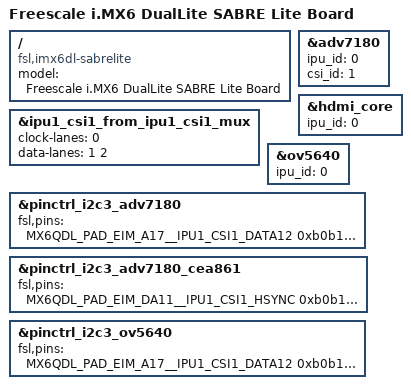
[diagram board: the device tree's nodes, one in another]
// SPDX-License-Identifier: GPL-2.0 OR X11
/*
 * Copyright 2013 Boundary Devices, Inc.
 * Copyright 2012 Freescale Semiconductor, Inc.
 * Copyright 2011 Linaro Ltd.
 */

/dts-v1/;
#include "imx6dl.dtsi"
#include "imx6qdl-sabrelite.dtsi"

/ {
	model = "Freescale i.MX6 DualLite SABRE Lite Board";
	compatible = "fsl,imx6dl-sabrelite", "fsl,imx6dl";
};

&adv7180 {
	ipu_id = <0>;
	csi_id = <1>;
};

&hdmi_core {
	ipu_id = <0>;
};

&ipu1_csi1_from_ipu1_csi1_mux {
	clock-lanes = <0>;
	data-lanes = <1 2>;
};

&ov5640 {
	ipu_id = <0>;
};

&pinctrl_i2c3_adv7180 {
	fsl,pins = <
		MX6QDL_PAD_EIM_A17__IPU1_CSI1_DATA12	0xb0b1
		MX6QDL_PAD_EIM_A18__IPU1_CSI1_DATA13	0xb0b1
		MX6QDL_PAD_EIM_A19__IPU1_CSI1_DATA14	0xb0b1
		MX6QDL_PAD_EIM_A20__IPU1_CSI1_DATA15	0xb0b1
		MX6QDL_PAD_EIM_A21__IPU1_CSI1_DATA16	0xb0b1
		MX6QDL_PAD_EIM_A22__IPU1_CSI1_DATA17	0xb0b1
		MX6QDL_PAD_EIM_A23__IPU1_CSI1_DATA18	0xb0b1
		MX6QDL_PAD_EIM_EB2__IPU1_CSI1_DATA19	0xb0b1
		MX6QDL_PAD_EIM_A16__IPU1_CSI1_PIXCLK	0xb0b1
       >;
};

&pinctrl_i2c3_adv7180_cea861 {
	fsl,pins = <
		MX6QDL_PAD_EIM_DA11__IPU1_CSI1_HSYNC	0xb0b1
		MX6QDL_PAD_EIM_DA12__IPU1_CSI1_VSYNC	0xb0b1
	>;
};

&pinctrl_i2c3_ov5640 { /* parallel camera */
	fsl,pins = <
		MX6QDL_PAD_EIM_A17__IPU1_CSI1_DATA12	0xb0b1
		MX6QDL_PAD_EIM_A18__IPU1_CSI1_DATA13	0xb0b1
		MX6QDL_PAD_EIM_A19__IPU1_CSI1_DATA14	0xb0b1
		MX6QDL_PAD_EIM_A20__IPU1_CSI1_DATA15	0xb0b1
		MX6QDL_PAD_EIM_A21__IPU1_CSI1_DATA16	0xb0b1
		MX6QDL_PAD_EIM_A22__IPU1_CSI1_DATA17	0xb0b1
		MX6QDL_PAD_EIM_A23__IPU1_CSI1_DATA18	0xb0b1
		MX6QDL_PAD_EIM_EB2__IPU1_CSI1_DATA19	0xb0b1
		MX6QDL_PAD_EIM_DA10__IPU1_CSI1_DATA_EN	0xb0b1
		MX6QDL_PAD_EIM_A16__IPU1_CSI1_PIXCLK	0xb0b1
		MX6QDL_PAD_EIM_DA11__IPU1_CSI1_HSYNC	0xb0b1
		MX6QDL_PAD_EIM_DA12__IPU1_CSI1_VSYNC	0xb0b1
	>;
};
